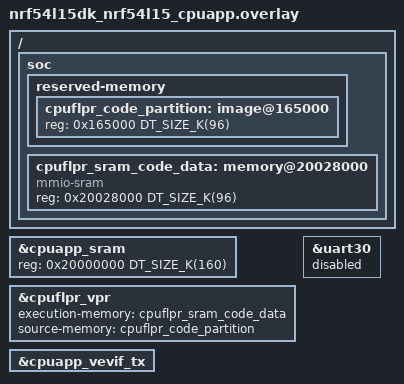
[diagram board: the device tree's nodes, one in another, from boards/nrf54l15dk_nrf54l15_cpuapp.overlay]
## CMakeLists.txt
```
cmake_minimum_required(VERSION 3.20.0)

find_package(Zephyr REQUIRED HINTS $ENV{ZEPHYR_BASE})

if(NOT SYSBUILD)
  message(FATAL_ERROR
    " This is a multi-image application that should be built using sysbuild.\n"
    " Add --sysbuild argument to west build command to prepare all the images."
  )
endif()

project(flpr_sleep_test)

target_sources(app PRIVATE src/main_app.c)
```

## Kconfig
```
config TEST_SLEEP_DURATION_MS
	int "Core sleep duration (milliseconds)"
	default 100
	help
	  Set the sleep duration for both APP and FLPR cores.  Based on the
	  'min-residency-us' values in the board DTS, the PM subsystem will
	  select the deepest achievable power state for the requested duration.

config APP_PROVIDE_PM_HOOKS
	bool "Application provides PM hooks"
	default y
	select HAS_PM
	select HAS_POWEROFF

config TEST_BASELINE_SLEEP
	bool "Sleep-forever baseline measurement mode"
	default n
	help
	  When enabled both cores sleep forever with no compute workload and no
	  GRTC wakeup.  Use this to measure the true system current floor.

source "Kconfig.zephyr"
```

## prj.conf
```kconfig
CONFIG_PM=y
CONFIG_POWEROFF=y
CONFIG_PM_DEVICE=y
CONFIG_PM_DEVICE_RUNTIME=y

CONFIG_LOG=y
CONFIG_CONSOLE=y
CONFIG_UART_CONSOLE=y
CONFIG_SERIAL=y
CONFIG_BOOT_BANNER=n
CONFIG_NCS_BOOT_BANNER=n
CONFIG_PRINTK=y

CONFIG_ASSERT=y
CONFIG_GPIO=y
```

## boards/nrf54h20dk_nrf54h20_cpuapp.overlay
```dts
/* Enable the FLPR core and reserve its UART. */
&cpuflpr_vpr {
	status = "okay";
};

&uart120 {
	status = "reserved";
	interrupt-parent = <&cpuflpr_clic>;
};
```

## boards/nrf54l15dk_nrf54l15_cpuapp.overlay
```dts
/*
 * Copyright (c) 2025 Nordic Semiconductor ASA
 *
 * SPDX-License-Identifier: LicenseRef-Nordic-5-Clause
 */

/ {
	soc {
		reserved-memory {
			#address-cells = <1>;
			#size-cells = <1>;

			cpuflpr_code_partition: image@165000 {
				reg = <0x165000 DT_SIZE_K(96)>;
			};
		};

		cpuflpr_sram_code_data: memory@20028000 {
			compatible = "mmio-sram";
			reg = <0x20028000 DT_SIZE_K(96)>;
			#address-cells = <1>;
			#size-cells = <1>;
			ranges = <0x0 0x20028000 0x18000>;
		};
	};
};

&cpuapp_sram {
	reg = <0x20000000 DT_SIZE_K(160)>;
	ranges = <0x0 0x20000000 0x28000>;
};

&cpuflpr_vpr {
	status = "okay";
	execution-memory = <&cpuflpr_sram_code_data>;
	source-memory = <&cpuflpr_code_partition>;
};

&cpuapp_vevif_tx {
	status = "okay";
};

&uart30 {
	status = "reserved";
};
```

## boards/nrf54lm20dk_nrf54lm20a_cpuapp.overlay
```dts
/ {
	soc {
		reserved-memory {
			#address-cells = <1>;
			#size-cells = <1>;

			cpuflpr_code_partition: image@1e5000 {
				reg = <0x1e5000 DT_SIZE_K(96)>;
			};
		};

		cpuflpr_sram_code_data: memory@20067c00 {
			compatible = "mmio-sram";
			reg = <0x20067c00 DT_SIZE_K(96)>;
			#address-cells = <1>;
			#size-cells = <1>;
			ranges = <0x0 0x20067c00 DT_SIZE_K(96)>;
		};
	};
};

&cpuapp_sram {
	reg = <0x20000000 DT_SIZE_K(415)>;
	ranges = <0x0 0x20000000 DT_SIZE_K(415)>;
};

&cpuflpr_vpr {
	status = "okay";
	execution-memory = <&cpuflpr_sram_code_data>;
	source-memory = <&cpuflpr_code_partition>;
};

&cpuapp_vevif_tx {
	status = "okay";
};

&uart30 {
	status = "reserved";
};
```

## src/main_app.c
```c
#include <zephyr/kernel.h>
#include <zephyr/logging/log.h>
#include <zephyr/pm/pm.h>
#include <hal/nrf_memconf.h>

LOG_MODULE_REGISTER(flpr_sleep_test, LOG_LEVEL_INF);


/*
 * The app core uses CONFIG_PM so the CPU enters a low power state during
 * k_sleep(K_FOREVER). These stubs satisfy the linker
 */
void pm_state_set(enum pm_state state, uint8_t substate_id)
{
	ARG_UNUSED(state);
	ARG_UNUSED(substate_id);
}

void pm_state_exit_post_ops(enum pm_state state, uint8_t substate_id)
{
	ARG_UNUSED(state);
	ARG_UNUSED(substate_id);
	irq_unlock(0);
}

int main(void)
{
#if !defined(CONFIG_TEST_BASELINE_SLEEP)
	LOG_INF("Multicore flpr_sleep_test on %s", CONFIG_BOARD_TARGET);
	LOG_INF("App core sleeping, FLPR running independently");
#endif

#if defined(CONFIG_SOC_NRF54LM20A) || defined(CONFIG_SOC_NRF54LM20A_ENGA)

	
	/* Disable unused blocks 1-14 */
	nrf_memconf_ramblock_ret_enable_set(NRF_MEMCONF, 0, MEMCONF_POWER_RET_MEM1_Pos,  false);
	nrf_memconf_ramblock_ret_enable_set(NRF_MEMCONF, 0, MEMCONF_POWER_RET_MEM2_Pos,  false);
	nrf_memconf_ramblock_ret_enable_set(NRF_MEMCONF, 0, MEMCONF_POWER_RET_MEM3_Pos,  false);
	nrf_memconf_ramblock_ret_enable_set(NRF_MEMCONF, 0, MEMCONF_POWER_RET_MEM4_Pos,  false);
	nrf_memconf_ramblock_ret_enable_set(NRF_MEMCONF, 0, MEMCONF_POWER_RET_MEM5_Pos,  false);
	nrf_memconf_ramblock_ret_enable_set(NRF_MEMCONF, 0, MEMCONF_POWER_RET_MEM6_Pos,  false);
	nrf_memconf_ramblock_ret_enable_set(NRF_MEMCONF, 0, MEMCONF_POWER_RET_MEM7_Pos,  false);
	nrf_memconf_ramblock_ret_enable_set(NRF_MEMCONF, 0, MEMCONF_POWER_RET_MEM8_Pos,  false);
	nrf_memconf_ramblock_ret_enable_set(NRF_MEMCONF, 0, MEMCONF_POWER_RET_MEM9_Pos,  false);
	nrf_memconf_ramblock_ret_enable_set(NRF_MEMCONF, 0, MEMCONF_POWER_RET_MEM10_Pos, false);
	nrf_memconf_ramblock_ret_enable_set(NRF_MEMCONF, 0, MEMCONF_POWER_RET_MEM11_Pos, false);
	nrf_memconf_ramblock_ret_enable_set(NRF_MEMCONF, 0, MEMCONF_POWER_RET_MEM12_Pos, false);
	nrf_memconf_ramblock_ret_enable_set(NRF_MEMCONF, 0, MEMCONF_POWER_RET_MEM13_Pos, false);
	nrf_memconf_ramblock_ret_enable_set(NRF_MEMCONF, 0, MEMCONF_POWER_RET_MEM14_Pos, false);
	
	/* Keep block 15 - FLPR VPR save area (RAM01 section 7) */
	nrf_memconf_ramblock_ret_enable_set(NRF_MEMCONF, 0, MEMCONF_POWER_RET_MEM15_Pos, true);
	/* Enable VPR context restore feature (block 32 = POWER[1].RET.MEM[0]) */
	nrf_memconf_ramblock_ret_enable_set(NRF_MEMCONF, 1, MEMCONF_POWER_RET_MEM0_Pos, true);


#elif defined(CONFIG_SOC_NRF54L15)

	/* Disable unused APP SRAM blocks 1-4 */
	nrf_memconf_ramblock_ret_enable_set(NRF_MEMCONF, 0, MEMCONF_POWER_RET_MEM1_Pos, false);
	nrf_memconf_ramblock_ret_enable_set(NRF_MEMCONF, 0, MEMCONF_POWER_RET_MEM2_Pos, false);
	nrf_memconf_ramblock_ret_enable_set(NRF_MEMCONF, 0, MEMCONF_POWER_RET_MEM3_Pos, false);
	nrf_memconf_ramblock_ret_enable_set(NRF_MEMCONF, 0, MEMCONF_POWER_RET_MEM4_Pos, false);
	/* Keep FLPR SRAM blocks 5-7 (0x20028000, 96 KB) */
	nrf_memconf_ramblock_ret_enable_set(NRF_MEMCONF, 0, MEMCONF_POWER_RET_MEM5_Pos, true);
	nrf_memconf_ramblock_ret_enable_set(NRF_MEMCONF, 0, MEMCONF_POWER_RET_MEM6_Pos, true);
	nrf_memconf_ramblock_ret_enable_set(NRF_MEMCONF, 0, MEMCONF_POWER_RET_MEM7_Pos, true);
	/* Enable VPR context restore feature (block 32 = POWER[1].RET.MEM[0]) */
	nrf_memconf_ramblock_ret_enable_set(NRF_MEMCONF, 1, MEMCONF_POWER_RET_MEM0_Pos, true);

#endif /* SOC selection */

	while (1) {
		k_sleep(K_FOREVER);
	}

	return 0;
}
```
